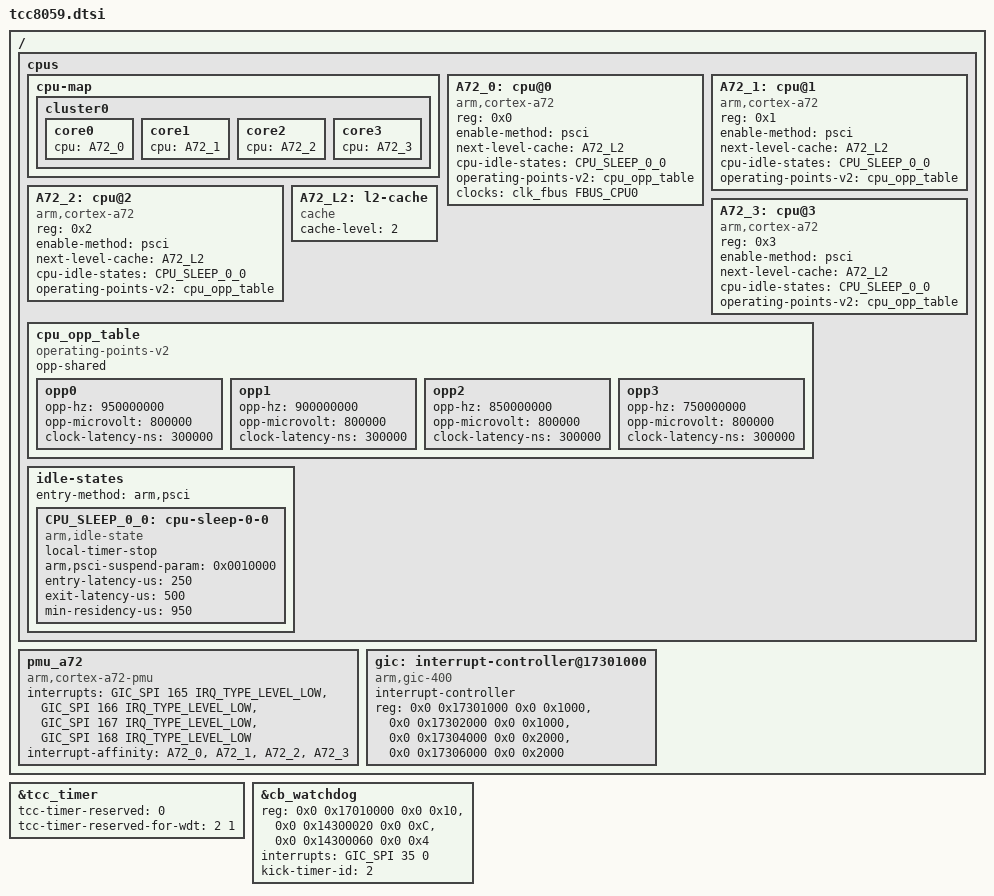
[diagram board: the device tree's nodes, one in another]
// SPDX-License-Identifier: (GPL-2.0-or-later OR MIT)
/*
 * Copyright (C) Telechips Inc.
 * Device tree for Telechips TCC8059 SoC
 */

#include "tcc805x.dtsi"
#include "tcc8059-pinctrl.dtsi"

/ {
	cpus {
		#address-cells = <1>;
		#size-cells = <0>;
		cpu-map {
			cluster0 {
				core0 {
					cpu = <&A72_0>;
				};
				core1 {
					cpu = <&A72_1>;
				};
				core2 {
					cpu = <&A72_2>;
				};
				core3 {
					cpu = <&A72_3>;
				};
			};
		};

		A72_0: cpu@0 {
			device_type = "cpu";
			compatible = "arm,cortex-a72";
			reg = <0x0>;
			enable-method = "psci";
			next-level-cache = <&A72_L2>;
			cpu-idle-states = <&CPU_SLEEP_0_0>;
			operating-points-v2 = <&cpu_opp_table>;
			clocks = <&clk_fbus FBUS_CPU0>;
			clock-names = "cpu0";
		};

		A72_1: cpu@1 {
			device_type = "cpu";
			compatible = "arm,cortex-a72";
			reg = <0x1>;
			enable-method = "psci";
			next-level-cache = <&A72_L2>;
			cpu-idle-states = <&CPU_SLEEP_0_0>;
			operating-points-v2 = <&cpu_opp_table>;
		};

		A72_2: cpu@2 {
			device_type = "cpu";
			compatible = "arm,cortex-a72";
			reg = <0x2>;
			enable-method = "psci";
			next-level-cache = <&A72_L2>;
			cpu-idle-states = <&CPU_SLEEP_0_0>;
			operating-points-v2 = <&cpu_opp_table>;
		};

		A72_3: cpu@3 {
			device_type = "cpu";
			compatible = "arm,cortex-a72";
			reg = <0x3>;
			enable-method = "psci";
			next-level-cache = <&A72_L2>;
			cpu-idle-states = <&CPU_SLEEP_0_0>;
			operating-points-v2 = <&cpu_opp_table>;
		};

		A72_L2: l2-cache {
			compatible = "cache";
			cache-level = <2>;
		};

		cpu_opp_table: cpu_opp_table {
			compatible = "operating-points-v2";
			opp-shared;

		        opp0 {
		                opp-hz = /bits/ 64 <950000000>;
		                opp-microvolt = <800000>;
		                clock-latency-ns = <300000>;
		        };
		        opp1 {
		                opp-hz = /bits/ 64 <900000000>;
		                opp-microvolt = <800000>;
		                clock-latency-ns = <300000>;
		        };

		        opp2 {
		                opp-hz = /bits/ 64 <850000000>;
		                opp-microvolt = <800000>;
		                clock-latency-ns = <300000>;
	               };
		        opp3 {
		                opp-hz = /bits/ 64 <750000000>;
		                opp-microvolt = <800000>;
		                clock-latency-ns = <300000>;
	               };
	       };

		idle-states {
			entry-method = "arm,psci";

			CPU_SLEEP_0_0: cpu-sleep-0-0 {
				compatible = "arm,idle-state";
				local-timer-stop;
				arm,psci-suspend-param = <0x0010000>;
				entry-latency-us = <250>;
				exit-latency-us = <500>;
				min-residency-us = <950>;
			};
		};
	};

	pmu_a72 {
		compatible = "arm,cortex-a72-pmu";
		interrupts = <GIC_SPI 165 IRQ_TYPE_LEVEL_LOW>,
			     <GIC_SPI 166 IRQ_TYPE_LEVEL_LOW>,
			     <GIC_SPI 167 IRQ_TYPE_LEVEL_LOW>,
			     <GIC_SPI 168 IRQ_TYPE_LEVEL_LOW>;
		interrupt-affinity = <&A72_0>,
				     <&A72_1>,
				     <&A72_2>,
				     <&A72_3>;
	};

	gic: interrupt-controller@17301000 {
		compatible = "arm,gic-400";
		#interrupt-cells = <3>;
		#address-cells = <0>;
		interrupt-controller;
		reg = <0x0 0x17301000 0x0 0x1000>,
		      <0x0 0x17302000 0x0 0x1000>,
		      <0x0 0x17304000 0x0 0x2000>,
		      <0x0 0x17306000 0x0 0x2000>;
	};
};

&tcc_timer {
	tcc-timer-reserved = <0>;
	tcc-timer-reserved-for-wdt = <2 1>;
};

&cb_watchdog {
    reg = <0x0 0x17010000 0x0 0x10>,
        <0x0 0x14300020 0x0 0xC>,
        <0x0 0x14300060 0x0 0x4>;
	interrupts = <GIC_SPI 35 0>;
	kick-timer-id = <2>;
};
